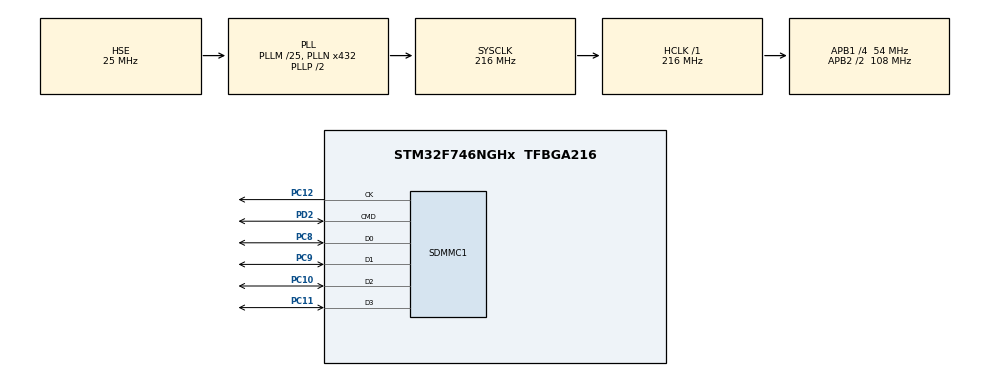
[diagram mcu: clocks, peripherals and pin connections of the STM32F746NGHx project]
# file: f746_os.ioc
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CORTEX_M7.CPU_DCache=Enabled
CORTEX_M7.CPU_ICache=Enabled
Dma.Request0=SDMMC1_RX
Dma.Request1=SDMMC1_TX
Dma.SDMMC1_RX.0.Direction=DMA_PERIPH_TO_MEMORY
Dma.SDMMC1_RX.0.FIFOMode=DMA_FIFOMODE_ENABLE
Dma.SDMMC1_RX.0.FIFOThreshold=DMA_FIFO_THRESHOLD_FULL
Dma.SDMMC1_RX.0.Instance=DMA2_Stream3
Dma.SDMMC1_RX.0.MemBurst=DMA_MBURST_INC4
Dma.SDMMC1_RX.0.MemDataAlignment=DMA_MDATAALIGN_WORD
Dma.SDMMC1_RX.0.MemInc=DMA_MINC_ENABLE
Dma.SDMMC1_RX.0.Mode=DMA_PFCTRL
Dma.SDMMC1_RX.0.PeriphBurst=DMA_PBURST_INC4
Dma.SDMMC1_RX.0.PeriphDataAlignment=DMA_PDATAALIGN_WORD
Dma.SDMMC1_RX.0.PeriphInc=DMA_PINC_DISABLE
Dma.SDMMC1_RX.0.Priority=DMA_PRIORITY_LOW
Dma.SDMMC1_TX.1.Direction=DMA_MEMORY_TO_PERIPH
Dma.SDMMC1_TX.1.FIFOMode=DMA_FIFOMODE_ENABLE
Dma.SDMMC1_TX.1.FIFOThreshold=DMA_FIFO_THRESHOLD_FULL
Dma.SDMMC1_TX.1.Instance=DMA2_Stream6
Dma.SDMMC1_TX.1.MemBurst=DMA_MBURST_INC4
Dma.SDMMC1_TX.1.MemDataAlignment=DMA_MDATAALIGN_WORD
Dma.SDMMC1_TX.1.MemInc=DMA_MINC_ENABLE
Dma.SDMMC1_TX.1.Mode=DMA_PFCTRL
Dma.SDMMC1_TX.1.PeriphBurst=DMA_PBURST_INC4
Dma.SDMMC1_TX.1.PeriphDataAlignment=DMA_PDATAALIGN_WORD
Dma.SDMMC1_TX.1.PeriphInc=DMA_PINC_DISABLE
Dma.SDMMC1_TX.1.Priority=DMA_PRIORITY_LOW
FATFS._USE_LFN=2
FREERTOS.Tasks01=defaultTask,0,128,StartDefaultTask,Default,NULL
Mcu.Family=STM32F7
Mcu.Name=STM32F746NGHx
Mcu.Package=TFBGA216
NVIC.DMA2_Stream3_IRQn=true\:5\:0\:false\:false\:true\:true\:false\:true
NVIC.DMA2_Stream6_IRQn=true\:5\:0\:false\:false\:true\:true\:false\:true
NVIC.PriorityGroup=NVIC_PRIORITYGROUP_4
NVIC.SDMMC1_IRQn=true\:5\:0\:false\:false\:true\:true\:true\:true
PC10.Mode=SD_4_bits_Wide_bus
PC10.Signal=SDMMC1_D2
PC11.Mode=SD_4_bits_Wide_bus
PC11.Signal=SDMMC1_D3
PC12.Mode=SD_4_bits_Wide_bus
PC12.Signal=SDMMC1_CK
PC8.Mode=SD_4_bits_Wide_bus
PC8.Signal=SDMMC1_D0
PC9.Mode=SD_4_bits_Wide_bus
PC9.Signal=SDMMC1_D1
PD2.Mode=SD_4_bits_Wide_bus
PD2.Signal=SDMMC1_CMD
PH0/OSC_IN.Mode=HSE-External-Oscillator
PH0/OSC_IN.Signal=RCC_OSC_IN
PH1/OSC_OUT.Mode=HSE-External-Oscillator
PH1/OSC_OUT.Signal=RCC_OSC_OUT
ProjectManager.HeapSize=0x1000
ProjectManager.StackSize=0x1000
ProjectManager.TargetToolchain=MDK-ARM V5
RCC.AHBFreq_Value=216000000
RCC.APB1CLKDivider=RCC_HCLK_DIV4
RCC.APB1Freq_Value=54000000
RCC.APB1TimFreq_Value=108000000
RCC.APB2CLKDivider=RCC_HCLK_DIV2
RCC.APB2Freq_Value=108000000
RCC.APB2TimFreq_Value=216000000
RCC.CortexFreq_Value=216000000
RCC.HCLKFreq_Value=216000000
RCC.HSE_VALUE=25000000
RCC.HSI_VALUE=16000000
RCC.LSE_VALUE=32768
RCC.PLLM=25
RCC.PLLN=432
RCC.PLLQ=9
RCC.PLLSourceVirtual=RCC_PLLSOURCE_HSE
RCC.SDMMCClockSelection=RCC_SDMMC1CLKSOURCE_CLK48
RCC.SYSCLKFreq_VALUE=216000000
RCC.SYSCLKSource=RCC_SYSCLKSOURCE_PLLCLK
RCC.USBFreq_Value=48000000
RCC.VCOOutputFreq_Value=432000000
VP_FATFS_VS_SDIO.Mode=SDIO
VP_FREERTOS_VS_CMSIS_V1.Mode=CMSIS_V1
board=custom

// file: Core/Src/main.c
/* USER CODE BEGIN Header */
/**
  ******************************************************************************
  * @file           : main.c
  * @brief          : Main program body
  ******************************************************************************
  * @attention
  *
  * <h2><center>&copy; Copyright (c) 2019 STMicroelectronics.
  * All rights reserved.</center></h2>
  *
  * This software component is licensed by ST under Ultimate Liberty license
  * SLA0044, the "License"; You may not use this file except in compliance with
  * the License. You may obtain a copy of the License at:
  *                             www.st.com/SLA0044
  *
  ******************************************************************************
  */
/* USER CODE END Header */

#include "main.h"
#include "cmsis_os.h"
#include "dma.h"
#include "fatfs.h"
#include "sdmmc.h"
#include "gpio.h"

void SystemClock_Config(void);
void MX_FREERTOS_Init(void);

int main(void)
{

  /* Enable I-Cache---------------------------------------------------------*/
  SCB_EnableICache();

  /* Enable D-Cache---------------------------------------------------------*/
  SCB_EnableDCache();

  /* MCU Configuration--------------------------------------------------------*/

  /* Reset of all peripherals, Initializes the Flash interface and the Systick. */
  HAL_Init();

  /* Configure the system clock */
  SystemClock_Config();

  /* Initialize all configured peripherals */
  MX_GPIO_Init();
  MX_DMA_Init();
  MX_SDMMC1_SD_Init();

  /* Call init function for freertos objects (in freertos.c) */
  MX_FREERTOS_Init();

  /* Start scheduler */
  osKernelStart();

  /* We should never get here as control is now taken by the scheduler */

  /* Infinite loop */
  while (1)
  {

  }
}

void SystemClock_Config(void)
{
  RCC_OscInitTypeDef RCC_OscInitStruct = {0};
  RCC_ClkInitTypeDef RCC_ClkInitStruct = {0};
  RCC_PeriphCLKInitTypeDef PeriphClkInitStruct = {0};

  /** Configure the main internal regulator output voltage
  */
  __HAL_RCC_PWR_CLK_ENABLE();
  __HAL_PWR_VOLTAGESCALING_CONFIG(PWR_REGULATOR_VOLTAGE_SCALE1);
  /** Initializes the CPU, AHB and APB busses clocks
  */
  RCC_OscInitStruct.OscillatorType = RCC_OSCILLATORTYPE_HSE;
  RCC_OscInitStruct.HSEState = RCC_HSE_ON;
  RCC_OscInitStruct.PLL.PLLState = RCC_PLL_ON;
  RCC_OscInitStruct.PLL.PLLSource = RCC_PLLSOURCE_HSE;
  RCC_OscInitStruct.PLL.PLLM = 25;
  RCC_OscInitStruct.PLL.PLLN = 432;
  RCC_OscInitStruct.PLL.PLLP = RCC_PLLP_DIV2;
  RCC_OscInitStruct.PLL.PLLQ = 9;
  if (HAL_RCC_OscConfig(&RCC_OscInitStruct) != HAL_OK)
  {
    Error_Handler();
  }
  /** Activate the Over-Drive mode
  */
  if (HAL_PWREx_EnableOverDrive() != HAL_OK)
  {
    Error_Handler();
  }
  /** Initializes the CPU, AHB and APB busses clocks
  */
  RCC_ClkInitStruct.ClockType = RCC_CLOCKTYPE_HCLK|RCC_CLOCKTYPE_SYSCLK
                              |RCC_CLOCKTYPE_PCLK1|RCC_CLOCKTYPE_PCLK2;
  RCC_ClkInitStruct.SYSCLKSource = RCC_SYSCLKSOURCE_PLLCLK;
  RCC_ClkInitStruct.AHBCLKDivider = RCC_SYSCLK_DIV1;
  RCC_ClkInitStruct.APB1CLKDivider = RCC_HCLK_DIV4;
  RCC_ClkInitStruct.APB2CLKDivider = RCC_HCLK_DIV2;

  if (HAL_RCC_ClockConfig(&RCC_ClkInitStruct, FLASH_LATENCY_7) != HAL_OK)
  {
    Error_Handler();
  }
  PeriphClkInitStruct.PeriphClockSelection = RCC_PERIPHCLK_SDMMC1|RCC_PERIPHCLK_CLK48;
  PeriphClkInitStruct.Clk48ClockSelection = RCC_CLK48SOURCE_PLL;
  PeriphClkInitStruct.Sdmmc1ClockSelection = RCC_SDMMC1CLKSOURCE_CLK48;
  if (HAL_RCCEx_PeriphCLKConfig(&PeriphClkInitStruct) != HAL_OK)
  {
    Error_Handler();
  }
}

void Error_Handler(void)
{
}

/************************ (C) COPYRIGHT STMicroelectronics *****END OF FILE****/

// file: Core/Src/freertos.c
/* USER CODE BEGIN Header */
/**
  ******************************************************************************
  * File Name          : freertos.c
  * Description        : Code for freertos applications
  ******************************************************************************
  * @attention
  *
  * <h2><center>&copy; Copyright (c) 2019 STMicroelectronics.
  * All rights reserved.</center></h2>
  *
  * This software component is licensed by ST under Ultimate Liberty license
  * SLA0044, the "License"; You may not use this file except in compliance with
  * the License. You may obtain a copy of the License at:
  *                             www.st.com/SLA0044
  *
  ******************************************************************************
  */
/* USER CODE END Header */

#include "FreeRTOS.h"
#include "task.h"
#include "main.h"
#include "cmsis_os.h"

osThreadId defaultTaskHandle;

/* USER CODE BEGIN FunctionPrototypes */
int test_main(void);
/* USER CODE END FunctionPrototypes */

void StartDefaultTask(void const * argument);

extern void MX_FATFS_Init(void);
void MX_FREERTOS_Init(void); /* (MISRA C 2004 rule 8.1) */

void MX_FREERTOS_Init(void) {

  /* Create the thread(s) */
  /* definition and creation of defaultTask */
  osThreadDef(defaultTask, StartDefaultTask, osPriorityNormal, 0, 800);
  defaultTaskHandle = osThreadCreate(osThread(defaultTask), NULL);

}

void StartDefaultTask(void const * argument)
{
  /* init code for FATFS */
  MX_FATFS_Init();

  /* USER CODE BEGIN StartDefaultTask */
	test_main();
  /* Infinite loop */
  for(;;)
  {
    osDelay(1);
  }
  /* USER CODE END StartDefaultTask */
}

/************************ (C) COPYRIGHT STMicroelectronics *****END OF FILE****/
